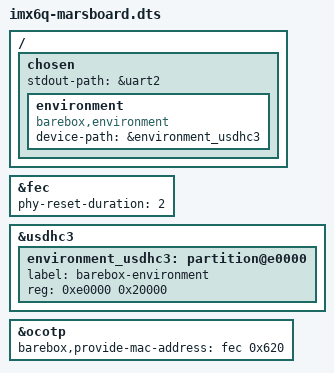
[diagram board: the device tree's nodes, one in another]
// SPDX-License-Identifier: GPL-2.0 OR X11
/*
 * Copyright (C) 2019 Ahmad Fatoum - Pengutronix
 */

#include <arm/imx6q-marsboard.dts>
#include "imx6qdl.dtsi"

/ {
	chosen {
		stdout-path = &uart2;

		environment {
			compatible = "barebox,environment";
			device-path = &environment_usdhc3;
		};
	};
};

&fec {
	phy-reset-duration = <2>;
};

&usdhc3 {
	#address-cells = <1>;
	#size-cells = <1>;

	environment_usdhc3: partition@e0000 {
		label = "barebox-environment";
		reg = <0xe0000 0x20000>;
	};
};

&ocotp {
	barebox,provide-mac-address = <&fec 0x620>;
};
